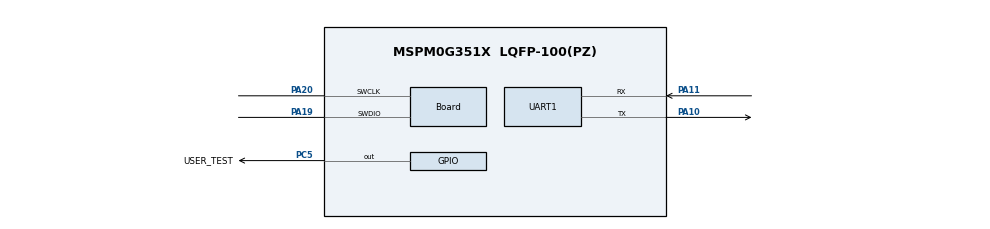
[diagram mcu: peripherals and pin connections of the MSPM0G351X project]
/**
 * @cliArgs --device "MSPM0G351X" --part "Default" --package "LQFP-100(PZ)" --product "mspm0_sdk@2.10.00.04"
 * @versions {"tool":"1.27.0+4565"}
 */

/**
 * Import the modules used in this configuration.
 */
const DMA     = scripting.addModule("/ti/driverlib/DMA");
const GPIO    = scripting.addModule("/ti/driverlib/GPIO", {}, false);
const GPIO1   = GPIO.addInstance();
const SYSCTL  = scripting.addModule("/ti/driverlib/SYSCTL");
const SYSTICK = scripting.addModule("/ti/driverlib/SYSTICK");
const UART    = scripting.addModule("/ti/driverlib/UART", {}, false);
const UART1   = UART.addInstance();

/**
 * Write custom configuration values to the imported modules.
 */
const divider9       = system.clockTree["UDIV"];
divider9.divideValue = 2;

const multiplier2         = system.clockTree["PLL_QDIV"];
multiplier2.multiplyValue = 4;

const mux4       = system.clockTree["EXHFMUX"];
mux4.inputSelect = "EXHFMUX_XTAL";

const mux8       = system.clockTree["HSCLKMUX"];
mux8.inputSelect = "HSCLKMUX_SYSPLL0";

const mux12       = system.clockTree["SYSPLLMUX"];
mux12.inputSelect = "zSYSPLLMUX_HFCLK";

const pinFunction4        = system.clockTree["HFXT"];
pinFunction4.enable       = true;
pinFunction4.HFXTStartup  = 10;
pinFunction4.HFCLKMonitor = true;
pinFunction4.inputFreq    = 40;

DMA.associatedChannels.create(1);
DMA.associatedChannels[0].$name = "DMA_CH1";

const Board                       = scripting.addModule("/ti/driverlib/Board", {}, false);
Board.peripheral.$assign          = "DEBUGSS";
Board.peripheral.swclkPin.$assign = "PA20";
Board.peripheral.swdioPin.$assign = "PA19";

GPIO1.$name                          = "GPIO_LEDS";
GPIO1.associatedPins.create(2);
GPIO1.associatedPins[0].$name        = "USER_LED_1";
GPIO1.associatedPins[0].initialValue = "SET";
GPIO1.associatedPins[0].assignedPort = "PORTC";
GPIO1.associatedPins[0].assignedPin  = "4";
GPIO1.associatedPins[1].$name        = "USER_TEST";
GPIO1.associatedPins[1].initialValue = "SET";
GPIO1.associatedPins[1].assignedPort = "PORTC";
GPIO1.associatedPins[1].assignedPin  = "5";
GPIO1.associatedPins[1].pin.$assign  = "PC5";

SYSCTL.forceDefaultClkConfig = true;
SYSCTL.clockTreeEn           = true;
SYSCTL.validateClkStatus     = true;

SYSTICK.periodEnable      = true;
SYSTICK.interruptEnable   = true;
SYSTICK.systickEnable     = true;
SYSTICK.period            = 80000;
SYSTICK.interruptPriority = "2";

UART1.$name                       = "UART_0";
UART1.enableDMATX                 = false;
UART1.enableFIFO                  = true;
UART1.rxFifoThreshold             = "DL_UART_RX_FIFO_LEVEL_ONE_ENTRY";
UART1.enabledDMARXTriggers        = "DL_UART_DMA_INTERRUPT_RX";
UART1.peripheral.$assign          = "UART0";
UART1.peripheral.rxPin.$assign    = "PA11";
UART1.peripheral.txPin.$assign    = "PA10";
UART1.txPinConfig.$name           = "ti_driverlib_gpio_GPIOPinGeneric0";
UART1.rxPinConfig.$name           = "ti_driverlib_gpio_GPIOPinGeneric1";
UART1.DMA_CHANNEL_RX.$name        = "DMA_CH0";
UART1.DMA_CHANNEL_RX.addressMode  = "f2b";
UART1.DMA_CHANNEL_RX.srcLength    = "BYTE";
UART1.DMA_CHANNEL_RX.dstLength    = "BYTE";
UART1.DMA_CHANNEL_RX.transferSize = 256;
UART1.DMA_CHANNEL_RX.transferMode = "FULL_CH_REPEAT_SINGLE";

const ProjectConfig              = scripting.addModule("/ti/project_config/ProjectConfig", {}, false);
ProjectConfig.migrationCondition = true;

/**
 * Pinmux solution for unlocked pins/peripherals. This ensures that minor changes to the automatic solver in a future
 * version of the tool will not impact the pinmux you originally saw.  These lines can be completely deleted in order to
 * re-solve from scratch.
 */
pinFunction4.peripheral.$suggestSolution              = "SYSCTL";
pinFunction4.peripheral.hfxInPin.$suggestSolution     = "PA5";
pinFunction4.peripheral.hfxOutPin.$suggestSolution    = "PA6";
DMA.associatedChannels[0].peripheral.$suggestSolution = "DMA_CH1";
GPIO1.associatedPins[0].pin.$suggestSolution          = "PC4";
UART1.DMA_CHANNEL_RX.peripheral.$suggestSolution      = "DMA_CH0";
